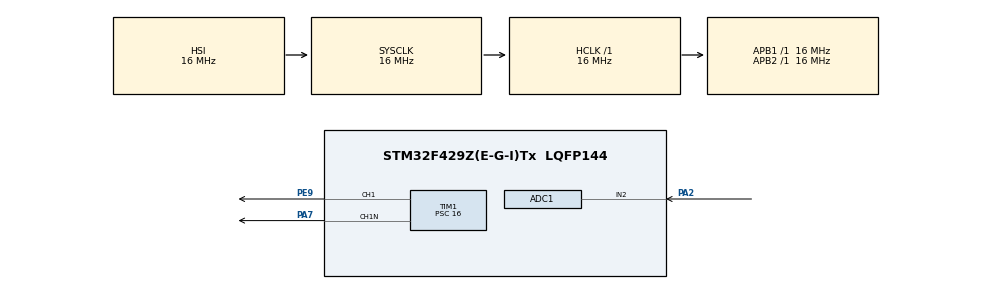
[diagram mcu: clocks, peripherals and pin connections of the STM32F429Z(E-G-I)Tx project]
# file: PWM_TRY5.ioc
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ADC1.Channel-0\#ChannelRegularConversion=ADC_CHANNEL_2
ADC1.ContinuousConvMode=ENABLE
ADC1.NbrOfConversionFlag=1
ADC1.Rank-0\#ChannelRegularConversion=1
ADC1.Resolution=ADC_RESOLUTION_8B
ADC1.SamplingTime-0\#ChannelRegularConversion=ADC_SAMPLETIME_144CYCLES
ADC1.master=1
Mcu.Family=STM32F4
Mcu.Name=STM32F429Z(E-G-I)Tx
Mcu.Package=LQFP144
NVIC.PriorityGroup=NVIC_PRIORITYGROUP_4
NVIC.TIM2_IRQn=true\:0\:0\:false\:false\:true
PA13.Mode=Trace_Asynchronous_SW
PA13.Signal=SYS_JTMS-SWDIO
PA14.Mode=Trace_Asynchronous_SW
PA14.Signal=SYS_JTCK-SWCLK
PA2.Signal=ADCx_IN2
PA7.Mode=PWM Generation1 CH1 CH1N
PA7.Signal=TIM1_CH1N
PB3.Mode=Trace_Asynchronous_SW
PB3.Signal=SYS_JTDO-SWO
PE9.Signal=S_TIM1_CH1
ProjectManager.HeapSize=0x200
ProjectManager.StackSize=0x400
ProjectManager.TargetToolchain=MDK-ARM V5
RCC.AHBFreq_Value=16000000
RCC.APB1Freq_Value=16000000
RCC.APB2Freq_Value=16000000
RCC.CortexFreq_Value=16000000
RCC.HSE_VALUE=25000000
RCC.HSI_VALUE=16000000
RCC.LSE_VALUE=32768
RCC.SYSCLKFreq_VALUE=16000000
RCC.VCOOutputFreq_Value=192000000
SH.ADCx_IN2.0=ADC1_IN2,IN2
SH.S_TIM1_CH1.0=TIM1_CH1,PWM Generation1 CH1 CH1N
TIM1.Period=100
TIM1.Prescaler=16
TIM1.Pulse-PWM\ Generation1\ CH1\ CH1N=50
TIM2.Period=100000
TIM2.Prescaler=16
VP_TIM1_VS_ClockSourceINT.Mode=Internal
VP_TIM2_VS_ClockSourceINT.Mode=Internal
board=PWM_TRY5

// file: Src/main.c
/**
  ******************************************************************************
  * File Name          : main.c
  * Description        : Main program body
  ******************************************************************************
  *
  * COPYRIGHT(c) 2017 STMicroelectronics
  *
  * Redistribution and use in source and binary forms, with or without modification,
  * are permitted provided that the following conditions are met:
  *   1. Redistributions of source code must retain the above copyright notice,
  *      this list of conditions and the following disclaimer.
  *   2. Redistributions in binary form must reproduce the above copyright notice,
  *      this list of conditions and the following disclaimer in the documentation
  *      and/or other materials provided with the distribution.
  *   3. Neither the name of STMicroelectronics nor the names of its contributors
  *      may be used to endorse or promote products derived from this software
  *      without specific prior written permission.
  *
  * THIS SOFTWARE IS PROVIDED BY THE COPYRIGHT HOLDERS AND CONTRIBUTORS "AS IS"
  * AND ANY EXPRESS OR IMPLIED WARRANTIES, INCLUDING, BUT NOT LIMITED TO, THE
  * IMPLIED WARRANTIES OF MERCHANTABILITY AND FITNESS FOR A PARTICULAR PURPOSE ARE
  * DISCLAIMED. IN NO EVENT SHALL THE COPYRIGHT HOLDER OR CONTRIBUTORS BE LIABLE
  * FOR ANY DIRECT, INDIRECT, INCIDENTAL, SPECIAL, EXEMPLARY, OR CONSEQUENTIAL
  * DAMAGES (INCLUDING, BUT NOT LIMITED TO, PROCUREMENT OF SUBSTITUTE GOODS OR
  * SERVICES; LOSS OF USE, DATA, OR PROFITS; OR BUSINESS INTERRUPTION) HOWEVER
  * CAUSED AND ON ANY THEORY OF LIABILITY, WHETHER IN CONTRACT, STRICT LIABILITY,
  * OR TORT (INCLUDING NEGLIGENCE OR OTHERWISE) ARISING IN ANY WAY OUT OF THE USE
  * OF THIS SOFTWARE, EVEN IF ADVISED OF THE POSSIBILITY OF SUCH DAMAGE.
  *
  ******************************************************************************
  */
#include "stm32f4xx_hal.h"
#include <math.h>

ADC_HandleTypeDef hadc1;

TIM_HandleTypeDef htim1;
TIM_HandleTypeDef htim2;

/* USER CODE BEGIN PV */
/* Private variables ---------------------------------------------------------*/

/* USER CODE END PV */

void SystemClock_Config(void);
void Error_Handler(void);
static void MX_GPIO_Init(void);
static void MX_ADC1_Init(void);
static void MX_TIM1_Init(void);
static void MX_TIM2_Init(void);

void HAL_TIM_MspPostInit(TIM_HandleTypeDef *htim);

/* USER CODE BEGIN PFP */
/* Private function prototypes -----------------------------------------------*/

/* USER CODE END PFP */

/* USER CODE BEGIN 0 */
void trace(char * string, uint8_t len){
	uint8_t i = 0;
	for(i=0; i<len;len++){
	ITM_SendChar(*string++);
	}
}
/* USER CODE END 0 */

int main(void)
{

  /* MCU Configuration----------------------------------------------------------*/

  /* Reset of all peripherals, Initializes the Flash interface and the Systick. */
  HAL_Init();

  /* Configure the system clock */
  SystemClock_Config();

  /* Initialize all configured peripherals */
  MX_GPIO_Init();
  MX_ADC1_Init();
  MX_TIM1_Init();
  MX_TIM2_Init();

  /* USER CODE BEGIN 2 */
HAL_TIM_PWM_Start(&htim1,TIM_CHANNEL_1);
HAL_TIM_Base_Start_IT(&htim2);
  /* USER CODE END 2 */

  /* Infinite loop */
  while (1)
  {

  }

}

/** System Clock Configuration
*/
void SystemClock_Config(void)
{

  RCC_OscInitTypeDef RCC_OscInitStruct;
  RCC_ClkInitTypeDef RCC_ClkInitStruct;

  __HAL_RCC_PWR_CLK_ENABLE();

  __HAL_PWR_VOLTAGESCALING_CONFIG(PWR_REGULATOR_VOLTAGE_SCALE3);

  RCC_OscInitStruct.OscillatorType = RCC_OSCILLATORTYPE_HSI;
  RCC_OscInitStruct.HSIState = RCC_HSI_ON;
  RCC_OscInitStruct.HSICalibrationValue = 16;
  RCC_OscInitStruct.PLL.PLLState = RCC_PLL_NONE;
  if (HAL_RCC_OscConfig(&RCC_OscInitStruct) != HAL_OK)
  {
    Error_Handler();
  }

  RCC_ClkInitStruct.ClockType = RCC_CLOCKTYPE_HCLK|RCC_CLOCKTYPE_SYSCLK
                              |RCC_CLOCKTYPE_PCLK1|RCC_CLOCKTYPE_PCLK2;
  RCC_ClkInitStruct.SYSCLKSource = RCC_SYSCLKSOURCE_HSI;
  RCC_ClkInitStruct.AHBCLKDivider = RCC_SYSCLK_DIV1;
  RCC_ClkInitStruct.APB1CLKDivider = RCC_HCLK_DIV1;
  RCC_ClkInitStruct.APB2CLKDivider = RCC_HCLK_DIV1;
  if (HAL_RCC_ClockConfig(&RCC_ClkInitStruct, FLASH_LATENCY_0) != HAL_OK)
  {
    Error_Handler();
  }

  HAL_SYSTICK_Config(HAL_RCC_GetHCLKFreq()/1000);

  HAL_SYSTICK_CLKSourceConfig(SYSTICK_CLKSOURCE_HCLK);

  /* SysTick_IRQn interrupt configuration */
  HAL_NVIC_SetPriority(SysTick_IRQn, 0, 0);
}

/* ADC1 init function */
static void MX_ADC1_Init(void)
{

  ADC_ChannelConfTypeDef sConfig;

    /**Configure the global features of the ADC (Clock, Resolution, Data Alignment and number of conversion)
    */
  hadc1.Instance = ADC1;
  hadc1.Init.ClockPrescaler = ADC_CLOCK_SYNC_PCLK_DIV2;
  hadc1.Init.Resolution = ADC_RESOLUTION_8B;
  hadc1.Init.ScanConvMode = DISABLE;
  hadc1.Init.ContinuousConvMode = ENABLE;
  hadc1.Init.DiscontinuousConvMode = DISABLE;
  hadc1.Init.ExternalTrigConvEdge = ADC_EXTERNALTRIGCONVEDGE_NONE;
  hadc1.Init.DataAlign = ADC_DATAALIGN_RIGHT;
  hadc1.Init.NbrOfConversion = 1;
  hadc1.Init.DMAContinuousRequests = ENABLE;
  hadc1.Init.EOCSelection = ADC_EOC_SINGLE_CONV;
  if (HAL_ADC_Init(&hadc1) != HAL_OK)
  {
    Error_Handler();
  }

    /**Configure for the selected ADC regular channel its corresponding rank in the sequencer and its sample time.
    */
  sConfig.Channel = ADC_CHANNEL_2;
  sConfig.Rank = 1;
  sConfig.SamplingTime = ADC_SAMPLETIME_144CYCLES;
  if (HAL_ADC_ConfigChannel(&hadc1, &sConfig) != HAL_OK)
  {
    Error_Handler();
  }

}

/* TIM1 init function */
static void MX_TIM1_Init(void)
{

  TIM_ClockConfigTypeDef sClockSourceConfig;
  TIM_MasterConfigTypeDef sMasterConfig;
  TIM_BreakDeadTimeConfigTypeDef sBreakDeadTimeConfig;
  TIM_OC_InitTypeDef sConfigOC;

  htim1.Instance = TIM1;
  htim1.Init.Prescaler = 16;
  htim1.Init.CounterMode = TIM_COUNTERMODE_UP;
  htim1.Init.Period = 100;
  htim1.Init.ClockDivision = TIM_CLOCKDIVISION_DIV1;
  htim1.Init.RepetitionCounter = 0;
  if (HAL_TIM_Base_Init(&htim1) != HAL_OK)
  {
    Error_Handler();
  }

  sClockSourceConfig.ClockSource = TIM_CLOCKSOURCE_INTERNAL;
  if (HAL_TIM_ConfigClockSource(&htim1, &sClockSourceConfig) != HAL_OK)
  {
    Error_Handler();
  }

  if (HAL_TIM_PWM_Init(&htim1) != HAL_OK)
  {
    Error_Handler();
  }

  sMasterConfig.MasterOutputTrigger = TIM_TRGO_RESET;
  sMasterConfig.MasterSlaveMode = TIM_MASTERSLAVEMODE_DISABLE;
  if (HAL_TIMEx_MasterConfigSynchronization(&htim1, &sMasterConfig) != HAL_OK)
  {
    Error_Handler();
  }

  sBreakDeadTimeConfig.OffStateRunMode = TIM_OSSR_DISABLE;
  sBreakDeadTimeConfig.OffStateIDLEMode = TIM_OSSI_DISABLE;
  sBreakDeadTimeConfig.LockLevel = TIM_LOCKLEVEL_OFF;
  sBreakDeadTimeConfig.DeadTime = 0;
  sBreakDeadTimeConfig.BreakState = TIM_BREAK_DISABLE;
  sBreakDeadTimeConfig.BreakPolarity = TIM_BREAKPOLARITY_HIGH;
  sBreakDeadTimeConfig.AutomaticOutput = TIM_AUTOMATICOUTPUT_DISABLE;
  if (HAL_TIMEx_ConfigBreakDeadTime(&htim1, &sBreakDeadTimeConfig) != HAL_OK)
  {
    Error_Handler();
  }

  sConfigOC.OCMode = TIM_OCMODE_PWM1;
  sConfigOC.Pulse = 50;
  sConfigOC.OCPolarity = TIM_OCPOLARITY_HIGH;
  sConfigOC.OCNPolarity = TIM_OCNPOLARITY_HIGH;
  sConfigOC.OCFastMode = TIM_OCFAST_DISABLE;
  sConfigOC.OCIdleState = TIM_OCIDLESTATE_RESET;
  sConfigOC.OCNIdleState = TIM_OCNIDLESTATE_RESET;
  if (HAL_TIM_PWM_ConfigChannel(&htim1, &sConfigOC, TIM_CHANNEL_1) != HAL_OK)
  {
    Error_Handler();
  }

  HAL_TIM_MspPostInit(&htim1);

}

/* TIM2 init function */
static void MX_TIM2_Init(void)
{

  TIM_ClockConfigTypeDef sClockSourceConfig;
  TIM_MasterConfigTypeDef sMasterConfig;

  htim2.Instance = TIM2;
  htim2.Init.Prescaler = 16;
  htim2.Init.CounterMode = TIM_COUNTERMODE_UP;
  htim2.Init.Period = 100000;
  htim2.Init.ClockDivision = TIM_CLOCKDIVISION_DIV1;
  if (HAL_TIM_Base_Init(&htim2) != HAL_OK)
  {
    Error_Handler();
  }

  sClockSourceConfig.ClockSource = TIM_CLOCKSOURCE_INTERNAL;
  if (HAL_TIM_ConfigClockSource(&htim2, &sClockSourceConfig) != HAL_OK)
  {
    Error_Handler();
  }

  sMasterConfig.MasterOutputTrigger = TIM_TRGO_RESET;
  sMasterConfig.MasterSlaveMode = TIM_MASTERSLAVEMODE_DISABLE;
  if (HAL_TIMEx_MasterConfigSynchronization(&htim2, &sMasterConfig) != HAL_OK)
  {
    Error_Handler();
  }

}

/** Configure pins as
        * Analog
        * Input
        * Output
        * EVENT_OUT
        * EXTI
*/
static void MX_GPIO_Init(void)
{

  /* GPIO Ports Clock Enable */
  __HAL_RCC_GPIOA_CLK_ENABLE();
  __HAL_RCC_GPIOE_CLK_ENABLE();
  __HAL_RCC_GPIOB_CLK_ENABLE();

}

/* USER CODE BEGIN 4 */
void HAL_TIM_PeriodElapsedCallback(TIM_HandleTypeDef *htim){
	HAL_ADC_Start(&hadc1);
	double pwmm = 0;
	pwmm = (double)HAL_ADC_GetValue(&hadc1);
	pwmm = (pwmm/256)*100;
	TIM1->CCR1 = round(pwmm);
	char temp[50];
	sprintf(temp, "pwm = %f \n",round(pwmm));
	trace(temp,50);
	//MX_TIM1_Init();
	//MX_ADC1_Init();

	//trace("Interrupt!\n",11);
}
/* USER CODE END 4 */

void Error_Handler(void)
{
  while(1)
  {
  }
}

/************************ (C) COPYRIGHT STMicroelectronics *****END OF FILE****/
